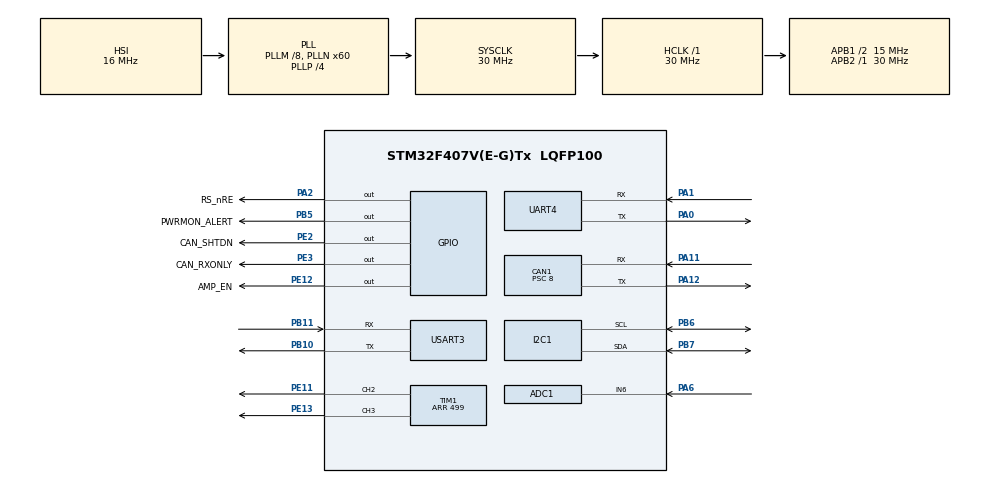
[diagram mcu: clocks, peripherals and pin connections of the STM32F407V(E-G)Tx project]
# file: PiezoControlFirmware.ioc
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ADC1.Channel-0\#ChannelRegularConversion=ADC_CHANNEL_6
ADC1.NbrOfConversionFlag=1
ADC1.Rank-0\#ChannelRegularConversion=1
ADC1.SamplingTime-0\#ChannelRegularConversion=ADC_SAMPLETIME_3CYCLES
ADC1.master=1
CAN1.BS1=CAN_BS1_7TQ
CAN1.BS2=CAN_BS2_2TQ
CAN1.CalculateBaudRate=187499
CAN1.CalculateTimeBit=5333
CAN1.CalculateTimeQuantum=533.3333333333334
CAN1.Prescaler=8
Dma.Request0=TIM1_CH2
Dma.Request1=TIM1_CH3
Dma.TIM1_CH2.0.Direction=DMA_MEMORY_TO_PERIPH
Dma.TIM1_CH2.0.FIFOMode=DMA_FIFOMODE_DISABLE
Dma.TIM1_CH2.0.Instance=DMA2_Stream2
Dma.TIM1_CH2.0.MemDataAlignment=DMA_MDATAALIGN_HALFWORD
Dma.TIM1_CH2.0.MemInc=DMA_MINC_ENABLE
Dma.TIM1_CH2.0.Mode=DMA_CIRCULAR
Dma.TIM1_CH2.0.PeriphDataAlignment=DMA_PDATAALIGN_HALFWORD
Dma.TIM1_CH2.0.PeriphInc=DMA_PINC_DISABLE
Dma.TIM1_CH2.0.Priority=DMA_PRIORITY_LOW
Dma.TIM1_CH3.1.Direction=DMA_MEMORY_TO_PERIPH
Dma.TIM1_CH3.1.FIFOMode=DMA_FIFOMODE_DISABLE
Dma.TIM1_CH3.1.Instance=DMA2_Stream6
Dma.TIM1_CH3.1.MemDataAlignment=DMA_MDATAALIGN_HALFWORD
Dma.TIM1_CH3.1.MemInc=DMA_MINC_ENABLE
Dma.TIM1_CH3.1.Mode=DMA_CIRCULAR
Dma.TIM1_CH3.1.PeriphDataAlignment=DMA_PDATAALIGN_HALFWORD
Dma.TIM1_CH3.1.PeriphInc=DMA_PINC_DISABLE
Dma.TIM1_CH3.1.Priority=DMA_PRIORITY_LOW
Mcu.Family=STM32F4
Mcu.Name=STM32F407V(E-G)Tx
Mcu.Package=LQFP100
NVIC.CAN1_RX0_IRQn=true\:0\:0\:false\:false\:true\:true\:true\:true
NVIC.CAN1_TX_IRQn=true\:0\:0\:false\:false\:true\:true\:true\:true
NVIC.DMA2_Stream2_IRQn=true\:0\:0\:false\:false\:true\:false\:true\:true
NVIC.DMA2_Stream6_IRQn=true\:0\:0\:false\:false\:true\:false\:true\:true
NVIC.PriorityGroup=NVIC_PRIORITYGROUP_4
PA0-WKUP.Mode=Asynchronous
PA0-WKUP.Signal=UART4_TX
PA1.Mode=Asynchronous
PA1.Signal=UART4_RX
PA11.Mode=CAN_Activate
PA11.Signal=CAN1_RX
PA12.Mode=CAN_Activate
PA12.Signal=CAN1_TX
PA13.Mode=Serial_Wire
PA13.Signal=SYS_JTMS-SWDIO
PA14.Mode=Serial_Wire
PA14.Signal=SYS_JTCK-SWCLK
PA2.GPIO_Label=RS_nRE
PA2.Signal=GPIO_Output
PA6.Signal=ADCx_IN6
PB10.Mode=Asynchronous
PB10.Signal=USART3_TX
PB11.Mode=Asynchronous
PB11.Signal=USART3_RX
PB5.GPIO_Label=PWRMON_ALERT
PB5.Signal=GPIO_Output
PB6.Mode=I2C
PB6.Signal=I2C1_SCL
PB7.Mode=I2C
PB7.Signal=I2C1_SDA
PE11.Signal=S_TIM1_CH2
PE12.GPIO_Label=AMP_EN
PE12.Signal=GPIO_Output
PE13.Signal=S_TIM1_CH3
PE2.GPIO_Label=CAN_SHTDN
PE2.Signal=GPIO_Output
PE3.GPIO_Label=CAN_RXONLY
PE3.Signal=GPIO_Output
PH0-OSC_IN.Mode=HSE-External-Oscillator
PH0-OSC_IN.Signal=RCC_OSC_IN
PH1-OSC_OUT.Mode=HSE-External-Oscillator
PH1-OSC_OUT.Signal=RCC_OSC_OUT
ProjectManager.HeapSize=0x200
ProjectManager.StackSize=0x400
ProjectManager.TargetToolchain=STM32CubeIDE
RCC.48MHZClocksFreq_Value=30000000
RCC.AHBFreq_Value=30000000
RCC.APB1CLKDivider=RCC_HCLK_DIV2
RCC.APB1Freq_Value=15000000
RCC.APB1TimFreq_Value=30000000
RCC.APB2Freq_Value=30000000
RCC.APB2TimFreq_Value=30000000
RCC.CortexFreq_Value=30000000
RCC.HCLKFreq_Value=30000000
RCC.HSE_VALUE=25000000
RCC.HSI_VALUE=16000000
RCC.LSE_VALUE=32768
RCC.PLLM=8
RCC.PLLN=60
RCC.PLLP=RCC_PLLP_DIV4
RCC.SYSCLKFreq_VALUE=30000000
RCC.SYSCLKSource=RCC_SYSCLKSOURCE_PLLCLK
RCC.VCOOutputFreq_Value=120000000
SH.ADCx_IN6.0=ADC1_IN6,IN6
SH.S_TIM1_CH2.0=TIM1_CH2,PWM Generation2 CH2
SH.S_TIM1_CH3.0=TIM1_CH3,PWM Generation3 CH3
TIM1.Channel-PWM\ Generation2\ CH2=TIM_CHANNEL_2
TIM1.Channel-PWM\ Generation3\ CH3=TIM_CHANNEL_3
TIM1.Period=499
UART4.VirtualMode=Asynchronous
USART3.VirtualMode=VM_ASYNC
board=custom

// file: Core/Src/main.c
/* USER CODE BEGIN Header */
/**
  ******************************************************************************
  * @file           : main.c
  * @brief          : Main program body
  ******************************************************************************
  * @attention
  *
  * Copyright (c) 2026 STMicroelectronics.
  * All rights reserved.
  *
  * This software is licensed under terms that can be found in the LICENSE file
  * in the root directory of this software component.
  * If no LICENSE file comes with this software, it is provided AS-IS.
  *
  ******************************************************************************
  */
/* USER CODE END Header */
#include "main.h"

/* USER CODE BEGIN Includes */
#include "CCR_sine.h"
/* USER CODE END Includes */

ADC_HandleTypeDef hadc1;
CAN_HandleTypeDef hcan1;
I2C_HandleTypeDef hi2c1;
TIM_HandleTypeDef htim1;
DMA_HandleTypeDef hdma_tim1_ch2;
DMA_HandleTypeDef hdma_tim1_ch3;
UART_HandleTypeDef huart4;
UART_HandleTypeDef huart3;

void SystemClock_Config(void);
static void MX_GPIO_Init(void);
static void MX_ADC1_Init(void);
static void MX_CAN1_Init(void);
static void MX_I2C1_Init(void);
static void MX_UART4_Init(void);
static void MX_DMA_Init(void);
static void MX_TIM1_Init(void);
static void MX_USART3_UART_Init(void);

int main(void)
{

  /* MCU Configuration--------------------------------------------------------*/

  /* Reset of all peripherals, Initializes the Flash interface and the Systick. */
  HAL_Init();

  /* Configure the system clock */
  SystemClock_Config();

  /* Initialize all configured peripherals */
  MX_GPIO_Init();
  MX_ADC1_Init();
  MX_CAN1_Init();
  MX_I2C1_Init();
  MX_UART4_Init();
  MX_DMA_Init();
  MX_TIM1_Init();
  MX_USART3_UART_Init();
  /* USER CODE BEGIN 2 */
  HAL_GPIO_WritePin(GPIOE, AMP_EN_Pin, GPIO_PIN_SET);
  HAL_TIM_PWM_Start_DMA(&htim1, TIM_CHANNEL_2, (uint32_t*)TrajSine,    NS);
  HAL_TIM_PWM_Start_DMA(&htim1, TIM_CHANNEL_3, (uint32_t*)TrajSineInv, NS);
  /* USER CODE END 2 */

  /* Infinite loop */
  while (1)
  {

  }
}

void SystemClock_Config(void)
{
  RCC_OscInitTypeDef RCC_OscInitStruct = {0};
  RCC_ClkInitTypeDef RCC_ClkInitStruct = {0};

  /** Configure the main internal regulator output voltage
  */
  __HAL_RCC_PWR_CLK_ENABLE();
  __HAL_PWR_VOLTAGESCALING_CONFIG(PWR_REGULATOR_VOLTAGE_SCALE1);

  /** Initializes the RCC Oscillators according to the specified parameters
  * in the RCC_OscInitTypeDef structure.
  */
  RCC_OscInitStruct.OscillatorType = RCC_OSCILLATORTYPE_HSI;
  RCC_OscInitStruct.HSIState = RCC_HSI_ON;
  RCC_OscInitStruct.HSICalibrationValue = RCC_HSICALIBRATION_DEFAULT;
  RCC_OscInitStruct.PLL.PLLState = RCC_PLL_ON;
  RCC_OscInitStruct.PLL.PLLSource = RCC_PLLSOURCE_HSI;
  RCC_OscInitStruct.PLL.PLLM = 8;
  RCC_OscInitStruct.PLL.PLLN = 60;
  RCC_OscInitStruct.PLL.PLLP = RCC_PLLP_DIV4;
  RCC_OscInitStruct.PLL.PLLQ = 4;
  if (HAL_RCC_OscConfig(&RCC_OscInitStruct) != HAL_OK)
  {
    Error_Handler();
  }

  /** Initializes the CPU, AHB and APB buses clocks
  */
  RCC_ClkInitStruct.ClockType = RCC_CLOCKTYPE_HCLK|RCC_CLOCKTYPE_SYSCLK
                              |RCC_CLOCKTYPE_PCLK1|RCC_CLOCKTYPE_PCLK2;
  RCC_ClkInitStruct.SYSCLKSource = RCC_SYSCLKSOURCE_PLLCLK;
  RCC_ClkInitStruct.AHBCLKDivider = RCC_SYSCLK_DIV1;
  RCC_ClkInitStruct.APB1CLKDivider = RCC_HCLK_DIV2;
  RCC_ClkInitStruct.APB2CLKDivider = RCC_HCLK_DIV1;

  if (HAL_RCC_ClockConfig(&RCC_ClkInitStruct, FLASH_LATENCY_0) != HAL_OK)
  {
    Error_Handler();
  }
}

static void MX_ADC1_Init(void)
{

  ADC_ChannelConfTypeDef sConfig = {0};

  /** Configure the global features of the ADC (Clock, Resolution, Data Alignment and number of conversion)
  */
  hadc1.Instance = ADC1;
  hadc1.Init.ClockPrescaler = ADC_CLOCK_SYNC_PCLK_DIV2;
  hadc1.Init.Resolution = ADC_RESOLUTION_12B;
  hadc1.Init.ScanConvMode = DISABLE;
  hadc1.Init.ContinuousConvMode = DISABLE;
  hadc1.Init.DiscontinuousConvMode = DISABLE;
  hadc1.Init.ExternalTrigConvEdge = ADC_EXTERNALTRIGCONVEDGE_NONE;
  hadc1.Init.ExternalTrigConv = ADC_SOFTWARE_START;
  hadc1.Init.DataAlign = ADC_DATAALIGN_RIGHT;
  hadc1.Init.NbrOfConversion = 1;
  hadc1.Init.DMAContinuousRequests = DISABLE;
  hadc1.Init.EOCSelection = ADC_EOC_SINGLE_CONV;
  if (HAL_ADC_Init(&hadc1) != HAL_OK)
  {
    Error_Handler();
  }

  /** Configure for the selected ADC regular channel its corresponding rank in the sequencer and its sample time.
  */
  sConfig.Channel = ADC_CHANNEL_6;
  sConfig.Rank = 1;
  sConfig.SamplingTime = ADC_SAMPLETIME_3CYCLES;
  if (HAL_ADC_ConfigChannel(&hadc1, &sConfig) != HAL_OK)
  {
    Error_Handler();
  }

}

static void MX_CAN1_Init(void)
{

  hcan1.Instance = CAN1;
  hcan1.Init.Prescaler = 8;
  hcan1.Init.Mode = CAN_MODE_NORMAL;
  hcan1.Init.SyncJumpWidth = CAN_SJW_1TQ;
  hcan1.Init.TimeSeg1 = CAN_BS1_7TQ;
  hcan1.Init.TimeSeg2 = CAN_BS2_2TQ;
  hcan1.Init.TimeTriggeredMode = DISABLE;
  hcan1.Init.AutoBusOff = DISABLE;
  hcan1.Init.AutoWakeUp = DISABLE;
  hcan1.Init.AutoRetransmission = DISABLE;
  hcan1.Init.ReceiveFifoLocked = DISABLE;
  hcan1.Init.TransmitFifoPriority = DISABLE;
  if (HAL_CAN_Init(&hcan1) != HAL_OK)
  {
    Error_Handler();
  }

}

static void MX_I2C1_Init(void)
{

  hi2c1.Instance = I2C1;
  hi2c1.Init.ClockSpeed = 100000;
  hi2c1.Init.DutyCycle = I2C_DUTYCYCLE_2;
  hi2c1.Init.OwnAddress1 = 0;
  hi2c1.Init.AddressingMode = I2C_ADDRESSINGMODE_7BIT;
  hi2c1.Init.DualAddressMode = I2C_DUALADDRESS_DISABLE;
  hi2c1.Init.OwnAddress2 = 0;
  hi2c1.Init.GeneralCallMode = I2C_GENERALCALL_DISABLE;
  hi2c1.Init.NoStretchMode = I2C_NOSTRETCH_DISABLE;
  if (HAL_I2C_Init(&hi2c1) != HAL_OK)
  {
    Error_Handler();
  }

}

static void MX_TIM1_Init(void)
{

  TIM_MasterConfigTypeDef sMasterConfig = {0};
  TIM_OC_InitTypeDef sConfigOC = {0};
  TIM_BreakDeadTimeConfigTypeDef sBreakDeadTimeConfig = {0};

  htim1.Instance = TIM1;
  htim1.Init.Prescaler = 0;
  htim1.Init.CounterMode = TIM_COUNTERMODE_UP;
  /* 30 MHz TIM1 clock: 30e6 / ((PSC+1)*(ARR+1)) = 60 kHz -> ARR = 499 */
  htim1.Init.Period = 499;
  htim1.Init.ClockDivision = TIM_CLOCKDIVISION_DIV1;
  htim1.Init.RepetitionCounter = 0;
  htim1.Init.AutoReloadPreload = TIM_AUTORELOAD_PRELOAD_DISABLE;
  if (HAL_TIM_PWM_Init(&htim1) != HAL_OK)
  {
    Error_Handler();
  }
  sMasterConfig.MasterOutputTrigger = TIM_TRGO_RESET;
  sMasterConfig.MasterSlaveMode = TIM_MASTERSLAVEMODE_DISABLE;
  if (HAL_TIMEx_MasterConfigSynchronization(&htim1, &sMasterConfig) != HAL_OK)
  {
    Error_Handler();
  }
  sConfigOC.OCMode = TIM_OCMODE_PWM1;
  sConfigOC.Pulse = 0;
  sConfigOC.OCPolarity = TIM_OCPOLARITY_HIGH;
  sConfigOC.OCNPolarity = TIM_OCNPOLARITY_HIGH;
  sConfigOC.OCFastMode = TIM_OCFAST_DISABLE;
  sConfigOC.OCIdleState = TIM_OCIDLESTATE_RESET;
  sConfigOC.OCNIdleState = TIM_OCNIDLESTATE_RESET;
  if (HAL_TIM_PWM_ConfigChannel(&htim1, &sConfigOC, TIM_CHANNEL_2) != HAL_OK)
  {
    Error_Handler();
  }
  if (HAL_TIM_PWM_ConfigChannel(&htim1, &sConfigOC, TIM_CHANNEL_3) != HAL_OK)
  {
    Error_Handler();
  }
  sBreakDeadTimeConfig.OffStateRunMode = TIM_OSSR_DISABLE;
  sBreakDeadTimeConfig.OffStateIDLEMode = TIM_OSSI_DISABLE;
  sBreakDeadTimeConfig.LockLevel = TIM_LOCKLEVEL_OFF;
  sBreakDeadTimeConfig.DeadTime = 0;
  sBreakDeadTimeConfig.BreakState = TIM_BREAK_DISABLE;
  sBreakDeadTimeConfig.BreakPolarity = TIM_BREAKPOLARITY_HIGH;
  sBreakDeadTimeConfig.AutomaticOutput = TIM_AUTOMATICOUTPUT_DISABLE;
  if (HAL_TIMEx_ConfigBreakDeadTime(&htim1, &sBreakDeadTimeConfig) != HAL_OK)
  {
    Error_Handler();
  }
  HAL_TIM_MspPostInit(&htim1);

}

static void MX_UART4_Init(void)
{

  huart4.Instance = UART4;
  huart4.Init.BaudRate = 115200;
  huart4.Init.WordLength = UART_WORDLENGTH_8B;
  huart4.Init.StopBits = UART_STOPBITS_1;
  huart4.Init.Parity = UART_PARITY_NONE;
  huart4.Init.Mode = UART_MODE_TX_RX;
  huart4.Init.HwFlowCtl = UART_HWCONTROL_NONE;
  huart4.Init.OverSampling = UART_OVERSAMPLING_16;
  if (HAL_UART_Init(&huart4) != HAL_OK)
  {
    Error_Handler();
  }

}

static void MX_USART3_UART_Init(void)
{

  huart3.Instance = USART3;
  huart3.Init.BaudRate = 115200;
  huart3.Init.WordLength = UART_WORDLENGTH_8B;
  huart3.Init.StopBits = UART_STOPBITS_1;
  huart3.Init.Parity = UART_PARITY_NONE;
  huart3.Init.Mode = UART_MODE_TX_RX;
  huart3.Init.HwFlowCtl = UART_HWCONTROL_NONE;
  huart3.Init.OverSampling = UART_OVERSAMPLING_16;
  if (HAL_UART_Init(&huart3) != HAL_OK)
  {
    Error_Handler();
  }

}

static void MX_DMA_Init(void)
{

  /* DMA controller clock enable */
  __HAL_RCC_DMA2_CLK_ENABLE();

  /* DMA interrupt init */
  /* DMA2_Stream2_IRQn interrupt configuration */
  HAL_NVIC_SetPriority(DMA2_Stream2_IRQn, 0, 0);
  HAL_NVIC_EnableIRQ(DMA2_Stream2_IRQn);
  /* DMA2_Stream6_IRQn interrupt configuration */
  HAL_NVIC_SetPriority(DMA2_Stream6_IRQn, 0, 0);
  HAL_NVIC_EnableIRQ(DMA2_Stream6_IRQn);

}

static void MX_GPIO_Init(void)
{
  GPIO_InitTypeDef GPIO_InitStruct = {0};

  /* GPIO Ports Clock Enable */
  __HAL_RCC_GPIOE_CLK_ENABLE();
  __HAL_RCC_GPIOH_CLK_ENABLE();
  __HAL_RCC_GPIOA_CLK_ENABLE();
  __HAL_RCC_GPIOB_CLK_ENABLE();

  /*Configure GPIO pin Output Level */
  HAL_GPIO_WritePin(GPIOE, CAN_SHTDN_Pin|CAN_RXONLY_Pin|AMP_EN_Pin, GPIO_PIN_RESET);

  /*Configure GPIO pin Output Level */
  HAL_GPIO_WritePin(RS_nRE_GPIO_Port, RS_nRE_Pin, GPIO_PIN_RESET);

  /*Configure GPIO pin Output Level */
  HAL_GPIO_WritePin(PWRMON_ALERT_GPIO_Port, PWRMON_ALERT_Pin, GPIO_PIN_RESET);

  /*Configure GPIO pins : CAN_SHTDN_Pin CAN_RXONLY_Pin AMP_EN_Pin */
  GPIO_InitStruct.Pin = CAN_SHTDN_Pin|CAN_RXONLY_Pin|AMP_EN_Pin;
  GPIO_InitStruct.Mode = GPIO_MODE_OUTPUT_PP;
  GPIO_InitStruct.Pull = GPIO_NOPULL;
  GPIO_InitStruct.Speed = GPIO_SPEED_FREQ_LOW;
  HAL_GPIO_Init(GPIOE, &GPIO_InitStruct);

  /*Configure GPIO pin : RS_nRE_Pin */
  GPIO_InitStruct.Pin = RS_nRE_Pin;
  GPIO_InitStruct.Mode = GPIO_MODE_OUTPUT_PP;
  GPIO_InitStruct.Pull = GPIO_NOPULL;
  GPIO_InitStruct.Speed = GPIO_SPEED_FREQ_LOW;
  HAL_GPIO_Init(RS_nRE_GPIO_Port, &GPIO_InitStruct);

  /*Configure GPIO pin : PWRMON_ALERT_Pin */
  GPIO_InitStruct.Pin = PWRMON_ALERT_Pin;
  GPIO_InitStruct.Mode = GPIO_MODE_OUTPUT_PP;
  GPIO_InitStruct.Pull = GPIO_NOPULL;
  GPIO_InitStruct.Speed = GPIO_SPEED_FREQ_LOW;
  HAL_GPIO_Init(PWRMON_ALERT_GPIO_Port, &GPIO_InitStruct);

}

void Error_Handler(void)
{
  __disable_irq();
  while (1)
  {
  }
}
